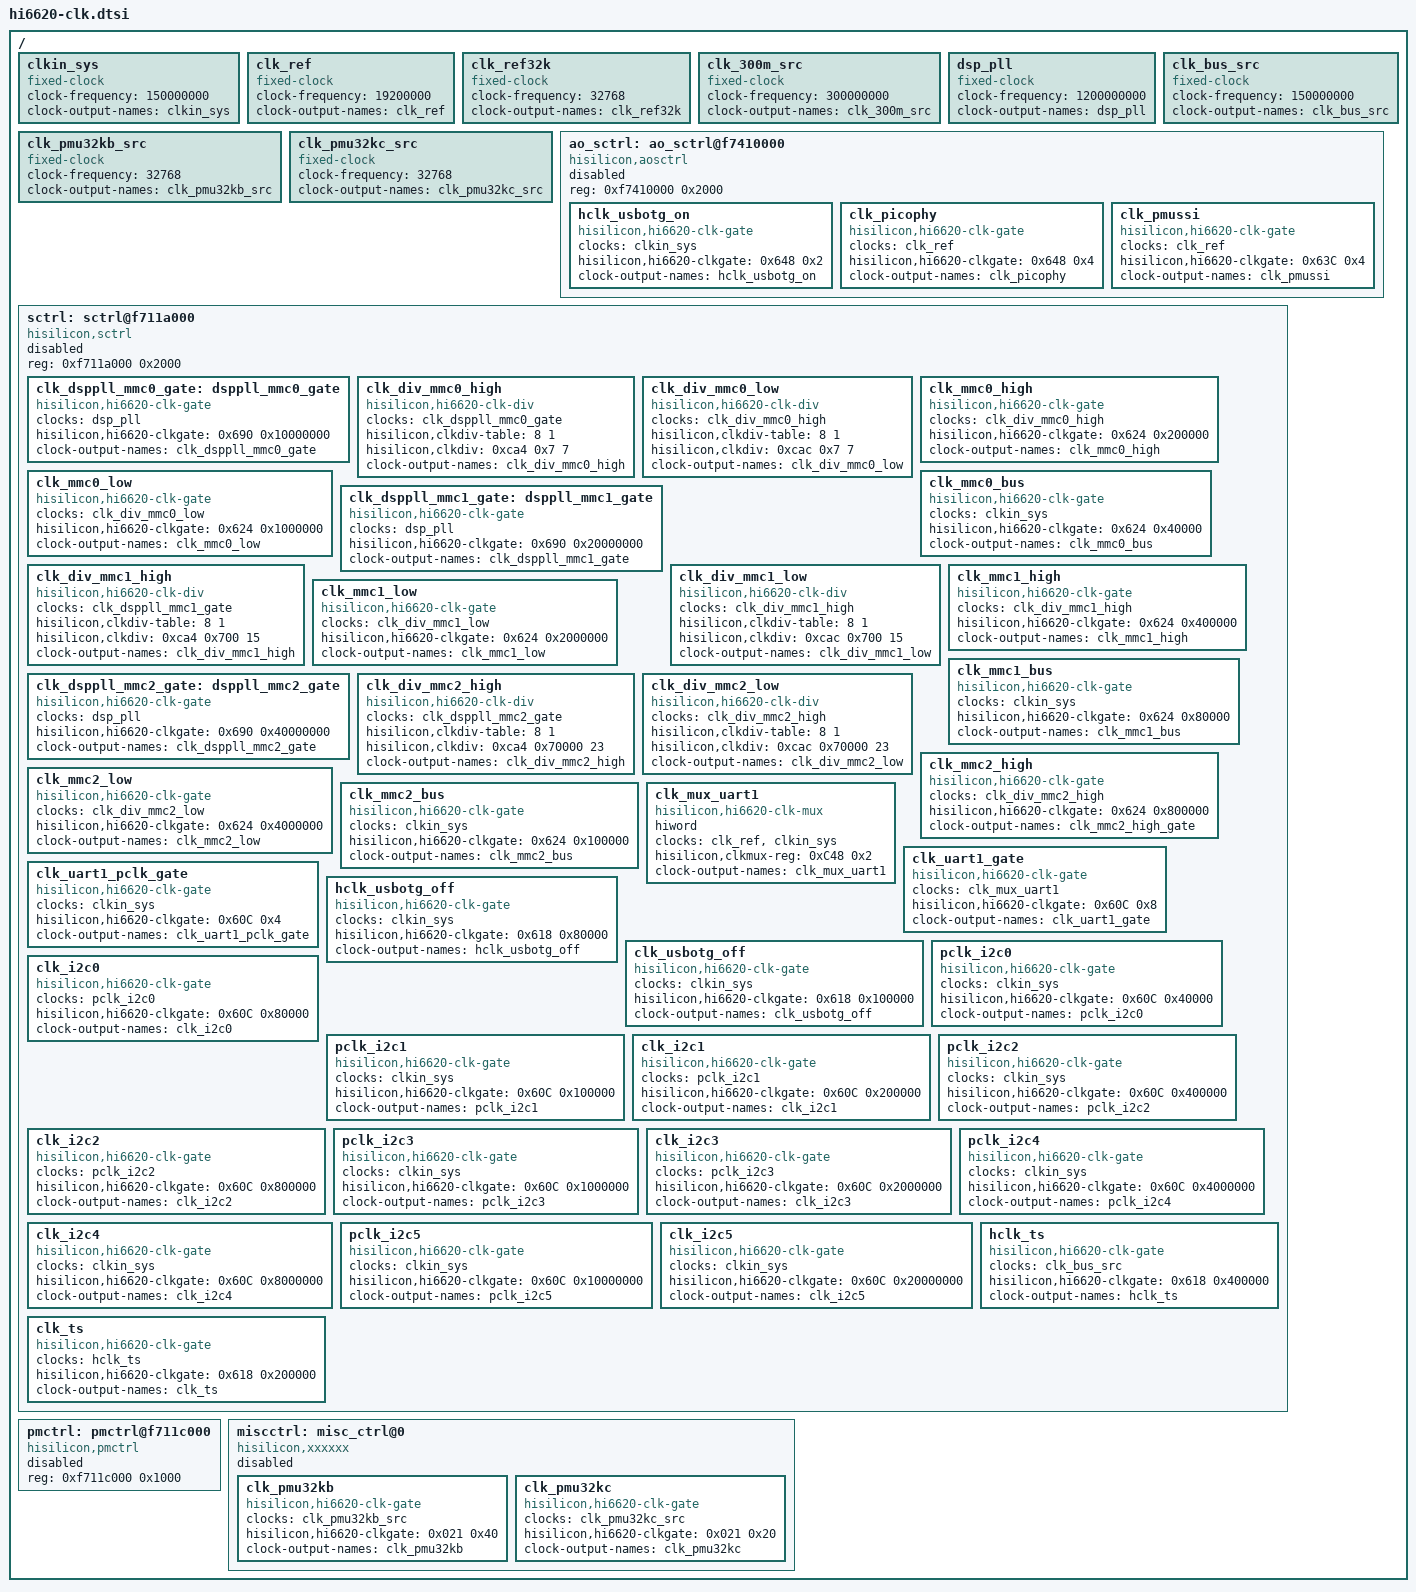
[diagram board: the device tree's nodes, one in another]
/ {
	/*------------fixed clock---------------*/
	clkin_sys: clkin_sys {
		compatible = "fixed-clock";
		#clock-cells = <0>;
		clock-frequency = <150000000>;
		clock-output-names = "clkin_sys";
	};

	clk_ref: clk_ref {
		compatible = "fixed-clock";
		#clock-cells = <0>;
		clock-frequency = <19200000>;
		clock-output-names = "clk_ref";
	};

	clk_ref32k: clk_ref32k {
		compatible = "fixed-clock";
		#clock-cells = <0>;
		clock-frequency = <32768>;
		clock-output-names = "clk_ref32k";
	};

	clk_300m_src: clk_300m_src {
		compatible = "fixed-clock";
		#clock-cells = <0>;
		clock-frequency = <300000000>;
		clock-output-names = "clk_300m_src";
	};

	dsp_pll: dsp_pll {
		compatible = "fixed-clock";
		#clock-cells = <0>;
		clock-frequency = <1200000000>;
		clock-output-names = "dsp_pll";
	};

	clk_bus_src: clk_bus_src {
		compatible = "fixed-clock";
		#clock-cells = <0>;
		clock-frequency = <150000000>;
		clock-output-names = "clk_bus_src";
	};

	/*pum clock configure*/
	clk_pmu32kb_src: clk_pmu32kb_src {
		compatible = "fixed-clock";
		#clock-cells = <0>;
		clock-frequency = <32768>;
		clock-output-names = "clk_pmu32kb_src";
	};

	clk_pmu32kc_src: clk_pmu32kc_src {
		compatible = "fixed-clock";
		#clock-cells = <0>;
		clock-frequency = <32768>;
		clock-output-names = "clk_pmu32kc_src";
	};

	/*---------------fixed clock end-----------*/

	/*------------------AO_SCTRL---------------*/	
	ao_sctrl: ao_sctrl@f7410000 {
		compatible = "hisilicon,aosctrl";
		reg = <0xf7410000 0x2000>;
		status = "disabled";

		/*usb clock configure*/
		hclk_usbotg_on: hclk_usbotg_on {
			compatible = "hisilicon,hi6620-clk-gate";
			#clock-cells = <0>;
			clocks = <&clkin_sys>;
			hisilicon,hi6620-clkgate = <0x648 0x2>;
			clock-output-names = "hclk_usbotg_on";
		};

		clk_picophy: clk_picophy {
			compatible = "hisilicon,hi6620-clk-gate";
			#clock-cells = <0>;
			clocks = <&clk_ref>;
			hisilicon,hi6620-clkgate = <0x648 0x4>;
			clock-output-names = "clk_picophy";
		};

		/*pmu ssi clock*/
		clk_pmussi: clk_pmussi {
			compatible = "hisilicon,hi6620-clk-gate";
			#clock-cells = <0>;
			clocks = <&clk_ref>;
			hisilicon,hi6620-clkgate = <0x63C 0x4>;
			clock-output-names = "clk_pmussi";
		};

	};
	/*----------------AO_SCTRL end-------------*/

	/*--------------------SCTRL----------------*/
	sctrl: sctrl@f711a000 {
		compatible = "hisilicon,sctrl";
		reg = <0xf711a000 0x2000>;
		status = "disabled";

		/*mmc0 clock configure*/
		clk_dsppll_mmc0_gate: dsppll_mmc0_gate {
			compatible = "hisilicon,hi6620-clk-gate";
			#clock-cells = <0>;
			clocks = <&dsp_pll>;
			hisilicon,hi6620-clkgate = <0x690 0x10000000>;
			clock-output-names = "clk_dsppll_mmc0_gate";
		};

		clk_div_mmc0_high: clk_div_mmc0_high {
			compatible = "hisilicon,hi6620-clk-div";
			#clock-cells = <0>;
			clocks = <&clk_dsppll_mmc0_gate>;
			hisilicon,clkdiv-table = <8 1>;
			/*divider register offset, bits, valid bit*/
			hisilicon,clkdiv = <0xca4 0x7 7>;
			clock-output-names = "clk_div_mmc0_high";
		};
		
		clk_div_mmc0_low: clk_div_mmc0_low {
			compatible = "hisilicon,hi6620-clk-div";
			#clock-cells = <0>;
			clocks = <&clk_div_mmc0_high>;
			hisilicon,clkdiv-table = <8 1>;
			/*divider register offset, bits, valid bit*/
			hisilicon,clkdiv = <0xcac 0x7 7>;
			clock-output-names = "clk_div_mmc0_low";
		};

		clk_mmc0_high: clk_mmc0_high {
			compatible = "hisilicon,hi6620-clk-gate";
			#clock-cells = <0>;
			clocks = <&clk_div_mmc0_high>;
			hisilicon,hi6620-clkgate = <0x624 0x200000>;
			clock-output-names = "clk_mmc0_high";
		};

		clk_mmc0_low: clk_mmc0_low {
			compatible = "hisilicon,hi6620-clk-gate";
			#clock-cells = <0>;
			clocks = <&clk_div_mmc0_low>;
			hisilicon,hi6620-clkgate = <0x624 0x1000000>;
			clock-output-names = "clk_mmc0_low";
		};

		clk_mmc0_bus: clk_mmc0_bus {
			compatible = "hisilicon,hi6620-clk-gate";
			#clock-cells = <0>;
			clocks = <&clkin_sys>;
			hisilicon,hi6620-clkgate = <0x624 0x40000>;
			clock-output-names = "clk_mmc0_bus";
		};
		
		/*mmc1 clock configure*/
		clk_dsppll_mmc1_gate: dsppll_mmc1_gate {
			compatible = "hisilicon,hi6620-clk-gate";
			#clock-cells = <0>;
			clocks = <&dsp_pll>;
			hisilicon,hi6620-clkgate = <0x690 0x20000000>;
			clock-output-names = "clk_dsppll_mmc1_gate";
		};

		clk_div_mmc1_high: clk_div_mmc1_high {
			compatible = "hisilicon,hi6620-clk-div";
			#clock-cells = <0>;
			clocks = <&clk_dsppll_mmc1_gate>;
			hisilicon,clkdiv-table = <8 1>;
			/*divider register offset, bits, valid bit*/
			hisilicon,clkdiv = <0xca4 0x700 15>;
			clock-output-names = "clk_div_mmc1_high";
		};
		
		clk_div_mmc1_low: clk_div_mmc1_low {
			compatible = "hisilicon,hi6620-clk-div";
			#clock-cells = <0>;
			clocks = <&clk_div_mmc1_high>;
			hisilicon,clkdiv-table = <8 1>;
			/*divider register offset, bits, valid bit*/
			hisilicon,clkdiv = <0xcac 0x700 15>;
			clock-output-names = "clk_div_mmc1_low";
		};

		clk_mmc1_high: clk_mmc1_high {
			compatible = "hisilicon,hi6620-clk-gate";
			#clock-cells = <0>;
			clocks = <&clk_div_mmc1_high>;
			hisilicon,hi6620-clkgate = <0x624 0x400000>;
			clock-output-names = "clk_mmc1_high";
		};

		clk_mmc1_low: clk_mmc1_low {
			compatible = "hisilicon,hi6620-clk-gate";
			#clock-cells = <0>;
			clocks = <&clk_div_mmc1_low>;
			hisilicon,hi6620-clkgate = <0x624 0x2000000>;
			clock-output-names = "clk_mmc1_low";
		};

		clk_mmc1_bus: clk_mmc1_bus {
			compatible = "hisilicon,hi6620-clk-gate";
			#clock-cells = <0>;
			clocks = <&clkin_sys>;
			hisilicon,hi6620-clkgate = <0x624 0x80000>;
			clock-output-names = "clk_mmc1_bus";
		};

		/*mmc2 clock configure*/
		clk_dsppll_mmc2_gate: dsppll_mmc2_gate {
			compatible = "hisilicon,hi6620-clk-gate";
			#clock-cells = <0>;
			clocks = <&dsp_pll>;
			hisilicon,hi6620-clkgate = <0x690 0x40000000>;
			clock-output-names = "clk_dsppll_mmc2_gate";
		};

		clk_div_mmc2_high: clk_div_mmc2_high {
			compatible = "hisilicon,hi6620-clk-div";
			#clock-cells = <0>;
			clocks = <&clk_dsppll_mmc2_gate>;
			hisilicon,clkdiv-table = <8 1>;
			/*divider register offset, bits, valid bit*/
			hisilicon,clkdiv = <0xca4 0x70000 23>;
			clock-output-names = "clk_div_mmc2_high";
		};
		
		clk_div_mmc2_low: clk_div_mmc2_low {
			compatible = "hisilicon,hi6620-clk-div";
			#clock-cells = <0>;
			clocks = <&clk_div_mmc2_high>;
			hisilicon,clkdiv-table = <8 1>;
			/*divider register offset, bits, valid bit*/
			hisilicon,clkdiv = <0xcac 0x70000 23>;
			clock-output-names = "clk_div_mmc2_low";
		};

		clk_mmc2_high: clk_mmc2_high {
			compatible = "hisilicon,hi6620-clk-gate";
			#clock-cells = <0>;
			clocks = <&clk_div_mmc2_high>;
			hisilicon,hi6620-clkgate = <0x624 0x800000>;
			clock-output-names = "clk_mmc2_high_gate";
		};

		clk_mmc2_low: clk_mmc2_low {
			compatible = "hisilicon,hi6620-clk-gate";
			#clock-cells = <0>;
			clocks = <&clk_div_mmc2_low>;
			hisilicon,hi6620-clkgate = <0x624 0x4000000>;
			clock-output-names = "clk_mmc2_low";
		};

		clk_mmc2_bus: clk_mmc2_bus {
			compatible = "hisilicon,hi6620-clk-gate";
			#clock-cells = <0>;
			clocks = <&clkin_sys>;
			hisilicon,hi6620-clkgate = <0x624 0x100000>;
			clock-output-names = "clk_mmc2_bus";
		};

		/*uart clock configure*/
		clk_mux_uart1: clk_mux_uart1 {
			compatible = "hisilicon,hi6620-clk-mux";
			#clock-cells = <0>;
			hiword;
			clocks = <&clk_ref &clkin_sys>;
			hisilicon,clkmux-reg = <0xC48 0x2>;
			clock-output-names = "clk_mux_uart1";
         };
		clk_uart1_gate: clk_uart1_gate {
			compatible = "hisilicon,hi6620-clk-gate";
			#clock-cells = <0>;
			clocks = <&clk_mux_uart1>;
			hisilicon,hi6620-clkgate = <0x60C 0x8>;
			clock-output-names = "clk_uart1_gate";
		};

		clk_uart1_pclk_gate: clk_uart1_pclk_gate {
			compatible = "hisilicon,hi6620-clk-gate";
			#clock-cells = <0>;
			clocks = <&clkin_sys>;
			hisilicon,hi6620-clkgate = <0x60C 0x4>;
			clock-output-names = "clk_uart1_pclk_gate";
		};

		/*USB clock configure*/
		hclk_usbotg_off: hclk_usbotg_off {
			compatible = "hisilicon,hi6620-clk-gate";
			#clock-cells = <0>;
			clocks = <&clkin_sys>;
			hisilicon,hi6620-clkgate = <0x618 0x80000>;
			clock-output-names = "hclk_usbotg_off";
		};
		clk_usbotg_off: clk_usbotg_off {
			compatible = "hisilicon,hi6620-clk-gate";
			#clock-cells = <0>;
			clocks = <&clkin_sys>;
			hisilicon,hi6620-clkgate = <0x618 0x100000>;
			clock-output-names = "clk_usbotg_off";
		};

		/*i2c clock configure*/
		pclk_i2c0: pclk_i2c0 {
			compatible = "hisilicon,hi6620-clk-gate";
			#clock-cells = <0>;
			clocks = <&clkin_sys>;
			hisilicon,hi6620-clkgate = <0x60C 0x40000>;
			clock-output-names = "pclk_i2c0";
		};
		clk_i2c0: clk_i2c0 {
			compatible = "hisilicon,hi6620-clk-gate";
			#clock-cells = <0>;
			clocks = <&pclk_i2c0>;
			hisilicon,hi6620-clkgate = <0x60C 0x80000>;
			clock-output-names = "clk_i2c0";
		};

		pclk_i2c1: pclk_i2c1 {
			compatible = "hisilicon,hi6620-clk-gate";
			#clock-cells = <0>;
			clocks = <&clkin_sys>;
			hisilicon,hi6620-clkgate = <0x60C 0x100000>;
			clock-output-names = "pclk_i2c1";
		};
		clk_i2c1: clk_i2c1 {
			compatible = "hisilicon,hi6620-clk-gate";
			#clock-cells = <0>;
			clocks = <&pclk_i2c1>;
			hisilicon,hi6620-clkgate = <0x60C 0x200000>;
			clock-output-names = "clk_i2c1";
		};

		pclk_i2c2: pclk_i2c2 {
			compatible = "hisilicon,hi6620-clk-gate";
			#clock-cells = <0>;
			clocks = <&clkin_sys>;
			hisilicon,hi6620-clkgate = <0x60C 0x400000>;
			clock-output-names = "pclk_i2c2";
		};
		clk_i2c2: clk_i2c2 {
			compatible = "hisilicon,hi6620-clk-gate";
			#clock-cells = <0>;
			clocks = <&pclk_i2c2>;
			hisilicon,hi6620-clkgate = <0x60C 0x800000>;
			clock-output-names = "clk_i2c2";
		};

		pclk_i2c3: pclk_i2c3 {
			compatible = "hisilicon,hi6620-clk-gate";
			#clock-cells = <0>;
			clocks = <&clkin_sys>;
			hisilicon,hi6620-clkgate = <0x60C 0x1000000>;
			clock-output-names = "pclk_i2c3";
		};
		clk_i2c3: clk_i2c3 {
			compatible = "hisilicon,hi6620-clk-gate";
			#clock-cells = <0>;
			clocks = <&pclk_i2c3>;
			hisilicon,hi6620-clkgate = <0x60C 0x2000000>;
			clock-output-names = "clk_i2c3";
		};

		pclk_i2c4: pclk_i2c4 {
			compatible = "hisilicon,hi6620-clk-gate";
			#clock-cells = <0>;
			clocks = <&clkin_sys>;
			hisilicon,hi6620-clkgate = <0x60C 0x4000000>;
			clock-output-names = "pclk_i2c4";
		};
		clk_i2c4: clk_i2c4 {
			compatible = "hisilicon,hi6620-clk-gate";
			#clock-cells = <0>;
			clocks = <&clkin_sys>;
			hisilicon,hi6620-clkgate = <0x60C 0x8000000>;
			clock-output-names = "clk_i2c4";
		};

		pclk_i2c5: pclk_i2c5 {
			compatible = "hisilicon,hi6620-clk-gate";
			#clock-cells = <0>;
			clocks = <&clkin_sys>;
			hisilicon,hi6620-clkgate = <0x60C 0x10000000>;
			clock-output-names = "pclk_i2c5";
		};
		clk_i2c5: clk_i2c5 {
			compatible = "hisilicon,hi6620-clk-gate";
			#clock-cells = <0>;
			clocks = <&clkin_sys>;
			hisilicon,hi6620-clkgate = <0x60C 0x20000000>;
			clock-output-names = "clk_i2c5";
		};

		/*ts clk conf*/
		hclk_ts: hclk_ts {
			compatible = "hisilicon,hi6620-clk-gate";
			#clock-cells = <0>;
			clocks = <&clk_bus_src>;
			hisilicon,hi6620-clkgate = <0x618 0x400000>;
			clock-output-names = "hclk_ts";
		};
		clk_ts: clk_ts {
			compatible = "hisilicon,hi6620-clk-gate";
			#clock-cells = <0>;
			clocks = <&hclk_ts>;
			hisilicon,hi6620-clkgate = <0x618 0x200000>;
			clock-output-names = "clk_ts";
		};

	};
	/*----------------SCTRL end-------------*/

	/*------------------PM_CTRL--------------*/
	pmctrl: pmctrl@f711c000 {
		compatible = "hisilicon,pmctrl";
		reg = <0xf711c000 0x1000>;
		status = "disabled";
	};
	/*-----------------PM_CTRL END--------------*/

	/*misc device clock*/
	miscctrl: misc_ctrl@0 {
		compatible = "hisilicon,xxxxxx";
		/*reg = <0x0 0x1000>;*/
		status = "disabled";

		/*pmu*/	
		clk_pmu32kb: clk_pmu32kb {
			compatible = "hisilicon,hi6620-clk-gate";
			#clock-cells = <0>;
			clocks = <&clk_pmu32kb_src>;
			hisilicon,hi6620-clkgate = <0x021 0x40>;
			clock-output-names = "clk_pmu32kb";
		};
		clk_pmu32kc: clk_pmu32kc {
			compatible = "hisilicon,hi6620-clk-gate";
			#clock-cells = <0>;
			clocks = <&clk_pmu32kc_src>;
			hisilicon,hi6620-clkgate = <0x021 0x20>;
			clock-output-names = "clk_pmu32kc";
		};

	};

};
